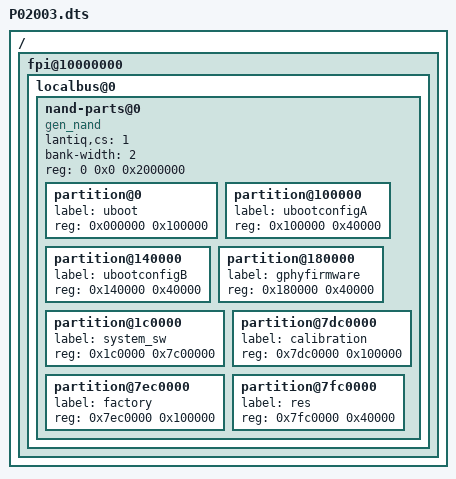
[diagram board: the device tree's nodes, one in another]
/dts-v1/;


/include/ "P02003_BOARD.dtsi"

/ {
	fpi@10000000 {
		localbus@0 {
			ranges = <0 0 0x4000000 0x3ffffff>;
			nand-parts@0 {
				compatible = "gen_nand", "lantiq,nand-xway";
				lantiq,cs = <1>;
				bank-width = <2>;
				reg = <0 0x0 0x2000000>;
				#address-cells = <1>;
				#size-cells = <1>;

				partition@0 {
					label = "uboot";
					reg = <0x000000 0x100000>;
				};

				partition@100000 {
					label = "ubootconfigA";
					reg = <0x100000 0x40000>;
				};

				partition@140000 {
					label = "ubootconfigB";
					reg = <0x140000 0x40000>;
				};

				partition@180000 {
					label = "gphyfirmware";
					reg = <0x180000 0x40000>;
				};

				partition@1c0000 {
					label = "system_sw";
					reg = <0x1c0000 0x7c00000>;
				};

				partition@7dc0000 {
					label = "calibration";
					reg = <0x7dc0000 0x100000>;
				};
				partition@7ec0000 {
					label = "factory";
					reg = <0x7ec0000 0x100000>;
				};
				partition@7fc0000 {
					label = "res";
					reg = <0x7fc0000 0x40000>;
				};

			};
		};
	};
};
